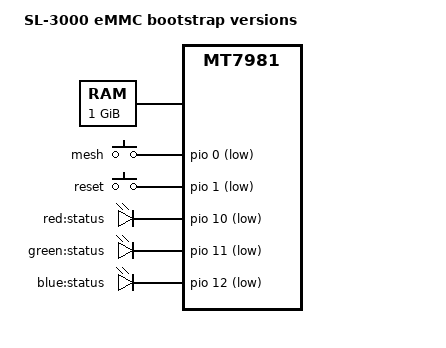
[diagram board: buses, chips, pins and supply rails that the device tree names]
// SPDX-License-Identifier: GPL-2.0-or-later OR MIT

/dts-v1/;
#include <dt-bindings/gpio/gpio.h>
#include <dt-bindings/input/input.h>
#include <dt-bindings/leds/common.h>
#include "mt7981.dtsi"

/ {
	model = "SL-3000 eMMC bootstrap versions";
	compatible = "sl,3000-emmc", "mediatek,mt7981";

	aliases {
		serial0 = &uart0;
		led-boot = &status_red_led;
		led-failsafe = &status_red_led;
		led-running = &status_green_led;
		led-upgrade = &status_blue_led;
	};

	chosen {
		bootargs = "root=PARTLABEL=rootfs rootwait";
		stdout-path = "serial0:115200n8";
	};

	/* 1GB RAM */
	memory@40000000 {
		reg = <0 0x40000000 0 0x40000000>;
	};

	gpio-keys {
		compatible = "gpio-keys";

		button-mesh {
			label = "mesh";
			linux,code = <BTN_9>;
			linux,input-type = <EV_SW>;
			gpios = <&pio 0 GPIO_ACTIVE_LOW>;
		};

		button-reset {
			label = "reset";
			linux,code = <KEY_RESTART>;
			gpios = <&pio 1 GPIO_ACTIVE_LOW>;
		};
	};

	gpio-leds {
		compatible = "gpio-leds";

		status_red_led: led-0 {
			label = "red:status";
			gpios = <&pio 10 GPIO_ACTIVE_LOW>;
		};

		status_green_led: led-1 {
			label = "green:status";
			gpios = <&pio 11 GPIO_ACTIVE_LOW>;
		};

		status_blue_led: led-2 {
			label = "blue:status";
			gpios = <&pio 12 GPIO_ACTIVE_LOW>;
		};
	};
};
